# W806 register map
Vendor: Beijing Lianshengde Micro-electronics Co., Ltd.; File version: 1.0
Registers are 32-bit, read-write, no defined reset value unless marked. A register's access mark holds for its fields unless they carry their own. Offsets are from the block's base; [hi:lo] are bit positions; {n}, {i} and the like mark numbered series.

## UART{n} — Universal Asynchronous Receiver/Transmitter
Base 0x40010600; array of 6, step 0x200
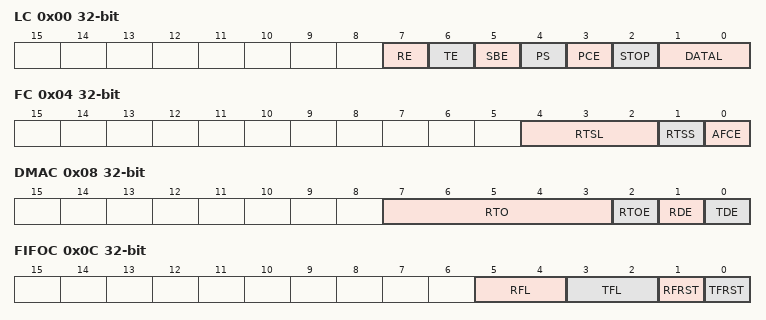
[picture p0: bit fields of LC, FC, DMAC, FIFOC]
0x00 LC — Line Control Register
  [7] RE — Receiver enable
  [6] TE — Transmitter enable
  [5] SBE — Send break enable
  [4] PS — Parity select
  [3] PCE — Parity control enable
  [2] STOP — Stop bits
  [1:0] DATAL — Data length
0x04 FC — Flow Control Register
  [4:2] RTSL — RTS level
  [1] RTSS — RTS select
  [0] AFCE — Auto flow control enable
0x08 DMAC — DMA Control Register
  [7:3] RTO — Receiver timeout
  [2] RTOE — Receiver timeout enable
  [1] RDE — Receiver DMA enable
  [0] TDE — Transmitter DMA enable
0x0C FIFOC — FIFO Control Register
  [5:4] RFL — Receiver FIFO level
  [3:2] TFL — Transmitter FIFO level
  [1] RFRST — Receiver FIFO reset
  [0] TFRST — Transmitter FIFO reset
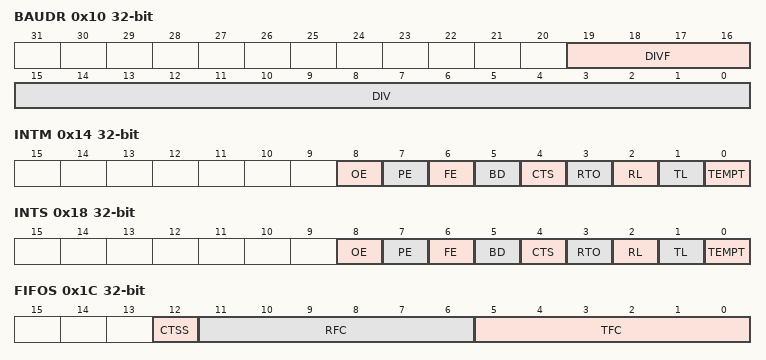
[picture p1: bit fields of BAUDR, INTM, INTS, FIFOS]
0x10 BAUDR — Baud Rate Register
  [19:16] DIVF — Fractional part of baud rate divider
  [15:0] DIV — Integer part of baud rate divider
0x14 INTM — Interrupt Mask Register
  [8] OE — Overrun error interrupt mask
  [7] PE — Parity error interrupt mask
  [6] FE — Framing error interrupt mask
  [5] BD — Break detected interrupt mask
  [4] CTS — CTS interrupt mask
  [3] RTO — Receiver timeout interrupt mask
  [2] RL — Receiver level interrupt mask
  [1] TL — Transmitter level interrupt mask
  [0] TEMPT — Transmitter empty interrupt mask
0x18 INTS — Interrupt Status Register
  [8] OE — Overrun error interrupt status
  [7] PE — Parity error interrupt status
  [6] FE — Framing error interrupt status
  [5] BD — Break detected interrupt status
  [4] CTS — CTS interrupt status
  [3] RTO — Receiver timeout interrupt status
  [2] RL — Receiver level interrupt status
  [1] TL — Transmitter level interrupt status
  [0] TEMPT — Transmitter empty interrupt status
0x1C FIFOS ro — FIFO Status Register
  [12] CTSS — CTS status
  [11:6] RFC — Receiver FIFO count
  [5:0] TFC — Transmitter FIFO count
0x20 TDW wo — Transmit Data Word Register
  [31:0] TDW — Transmit data word
{0x20+4i} RSV{i} (i=1..3) — Reserved
0x30 RDW ro — Receive Data Word Register
  [31:0] RDW — Receive data word

## TIMER
Base 0x40011800
0x00 TMR_CONFIG — Timer standard us configuration register
  [6:0] PRESCALE — Clock prescaler configuration
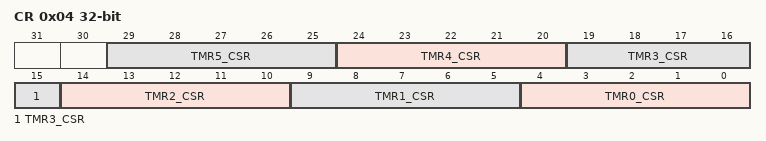
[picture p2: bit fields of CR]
0x04 CR — Timer control register
  [5n+4:5n] TMR{n}_CSR (n=0..5) — Timer control and status register
{0x8+4i} TIM{i}_PRD (i=0..5) — Timer period register
{0x20+4i} TIM{i}_CNT (i=0..5) ro — Timer count register

## GPIO[{x}] — General purpose input/output module
Base 0x40011200; array of 2, step 0x200
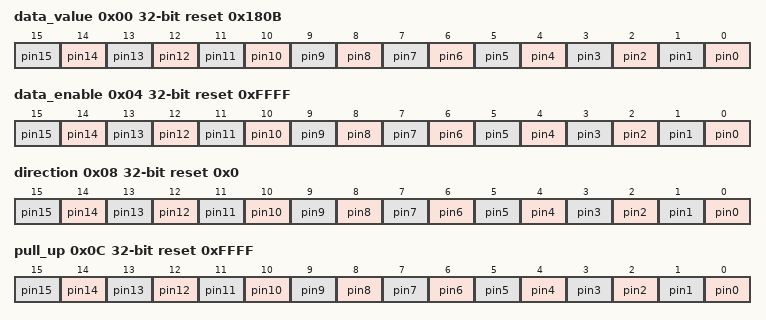
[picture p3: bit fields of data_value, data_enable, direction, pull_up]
0x00 data_value reset 0x180B — GPIO data value read/write register
  [n] pin{n} (n=0..15) — GPIO pin current data value
0x04 data_enable reset 0xFFFF — GPIO data read/write enable register
  [n] pin{n} (n=0..15) — GPIO pin read/write enable
0x08 direction reset 0x0 — GPIO direction register
  [n] pin{n} (n=0..15) — GPIO pin read/write enable
    0=input (The GPIO pin is input.); 1=output (The GPIO pin is output.)
0x0C pull_up reset 0xFFFF — Internal pull up mask register
  [n] pin{n} (n=0..15) — Internal pull up enable mask . Write 0 to enable.
    0=enable (Internal pull up enabled.); 1=disable (Internal pull up disabled.)
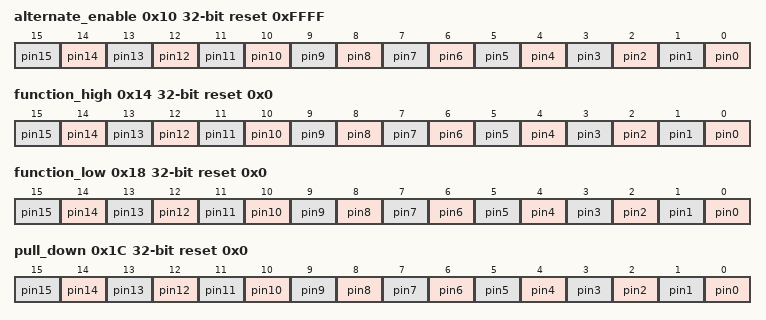
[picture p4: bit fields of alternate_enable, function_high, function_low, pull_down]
0x10 alternate_enable reset 0xFFFF — Alternate function enable register . Each bit corresponds to whether the corresponding GPIO multiplexing function is turned on. . When the bit is set, the multiplexing function depends on the corresponding bits of registers `function_high` and `function_low`.
  [n] pin{n} (n=0..15) — Alternate function enable.
    0=Disable alternate function; 1=Enable alternate function
0x14 function_high reset 0x0 — Alternate function select high register . This register and `function_low` jointly determine multiplexing function number.
  [n] pin{n} (n=0..15) — Alternate function high bit.
0x18 function_low reset 0x0 — Alternate function select low register . This register and `function_high` jointly determine multiplexing function number.
  [n] pin{n} (n=0..15) — Alternate function low bit.
0x1C pull_down reset 0x0 — Internal pull down register
  [n] pin{n} (n=0..15) — Internal pull down enable mask . Write 0 to enable.
    0=enable (Internal pull down enabled.); 1=disable (Internal pull down disabled.)
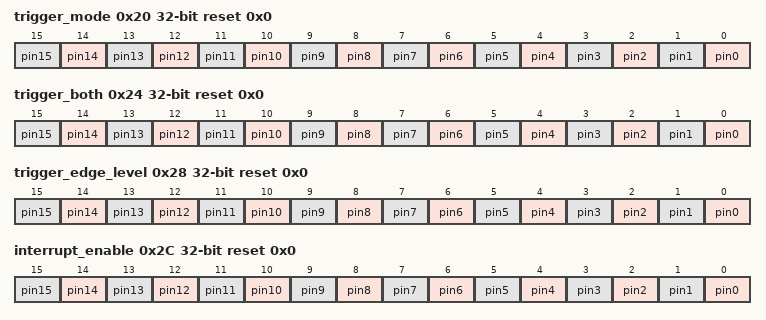
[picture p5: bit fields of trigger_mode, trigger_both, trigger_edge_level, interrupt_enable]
0x20 trigger_mode reset 0x0 — Interrupt trigger mode selection
  [n] pin{n} (n=0..15)
    0=Edge trigger; 1=Level trigger
0x24 trigger_both reset 0x0 — Interrupt trigger on both sides selection
  [n] pin{n} (n=0..15)
    0=single (Only edge defined in `trigger_edge_level` will trigger interrupt.); 1=Both edges or levels will trigger interrupt
0x28 trigger_edge_level reset 0x0 — Interrupt trigger edge or level type selection
  [n] pin{n} (n=0..15)
    0=low_or_fall (Low level or falling edge will trigger interrupt.); 1=high_or_rise (High level or rising edge will trigger interrupt.)
0x2C interrupt_enable reset 0x0
  [n] pin{n} (n=0..15) — GPIO pin interrupt enable
    0=Disable GPIO pin interrupt; 1=Enable GPIO pin interrupt
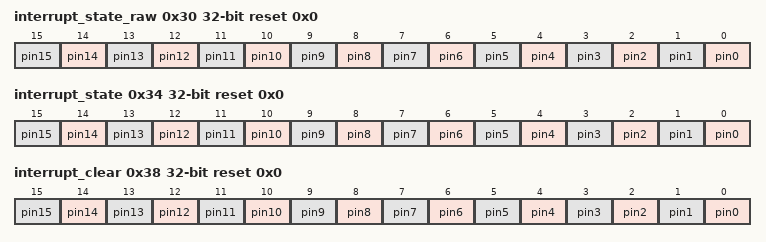
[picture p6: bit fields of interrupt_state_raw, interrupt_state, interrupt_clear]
0x30 interrupt_state_raw reset 0x0 — Raw interrupt state register . GPIO bare interrupt status before masking.
  [n] pin{n} (n=0..15) — GPIO pin raw interrupt state
    0=no_interrupt (No GPIO pin interrupt is generated.); 1=has_interrupt (GPIO pin interrupt is generated.)
0x34 interrupt_state reset 0x0 — Masked interrupt state register
  [n] pin{n} (n=0..15) — GPIO pin masked interrupt state
    0=no_interrupt (No GPIO pin interrupt is generated after masking.); 1=has_interrupt (GPIO pin interrupt is generated after masking.)
0x38 interrupt_clear wo reset 0x0 — Clear interrupt register
  [n] pin{n} (n=0..15) — GPIO pin masked interrupt state
    1=clear (Write 1 to clear GPIO interrupt state.)
